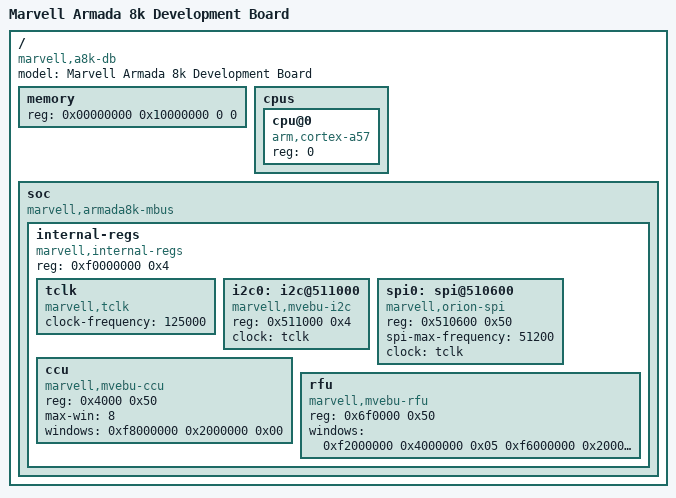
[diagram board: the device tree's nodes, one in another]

/dts-v1/;

/ {
	model = "Marvell Armada 8k Development Board";
	compatible = "marvell,a8k-db", "marvell,armada8k";

	#address-cells = <2>;
	#size-cells = <2>;

	memory {
		device_type = "memory";
		reg = <0x00000000 0x10000000 0 0>; /* 256 MB */
	};

	cpus {
		#address-cells = <1>;
		#size-cells = <0>;
		cpu@0 {
			device_type = "cpu";
			compatible = "arm,cortex-a57";
			reg = <0>;
		};
	};

	soc {
		compatible = "marvell,armada8k-mbus";
		#address-cells = <1>;
		#size-cells = <0>;

		internal-regs {
			compatible = "marvell,internal-regs";
			#address-cells = <1>;
			#size-cells = <1>;
			reg = <0xf0000000 0x4>;

			tclk: tclk {
				compatible = "marvell,tclk";
				#clock-cells = <0>;
				clock-frequency = <125000>;
			};
			i2c0: i2c@511000 {
				compatible = "marvell,mvebu-i2c";
				reg = <0x511000 0x4>;
				clock = <&tclk>;
				status = "okay";
			};

			spi0: spi@510600 {
				compatible = "marvell,orion-spi";
				reg = <0x510600 0x50>;
				spi-max-frequency = <51200>;
				clock = <&tclk>;
				status = "okay";
			};
			ccu {
				compatible = "marvell,mvebu-ccu";
				reg = <0x4000 0x50>;
				max-win = <8>;
				windows = <0xf8000000 0x2000000 0x00 /* IO window */>;
			};
			rfu {
				compatible = "marvell,mvebu-rfu";
				reg = <0x6f0000 0x50>;
				windows = <0xf2000000 0x4000000 0x05 /* PCIe window */
					0xf6000000 0x2000000 0x02 /* PCI-REG window */>;
			};
		};
	};
};
